# ESP32 register map
Vendor: ESPRESSIF SYSTEMS (SHANGHAI) CO., LTD.; Series: ESP32 Series; File version: 17
CPU: Xtensa LX6 r0p0, little endian, no MPU, FPU, 0 interrupt priority bits
Address unit: 32 bits
Registers are 32-bit, read-write, reset 0x0 unless marked. A register's access mark holds for its fields unless they carry their own. Offsets are from the block's base; [hi:lo] are bit positions; lines under a group give offsets from that group; {n}, {i} and the like mark numbered series.

## MCPWM0 — Motor Control Pulse Width Modulator (MCPWM) Peripheral
Base 0x3FF5E000
Same registers: MCPWM1 0x3FF6C000
0x00 CLK_CFG
  [7:0] CLK_PRESCALE
{0x4+0x10*i} TIMER{i} (i=0..2) group — Cluster TIMER{i}, containing TIMER?_CFG0, TIMER?_CFG1, TIMER?_SYNC, TIMER?_STATUS
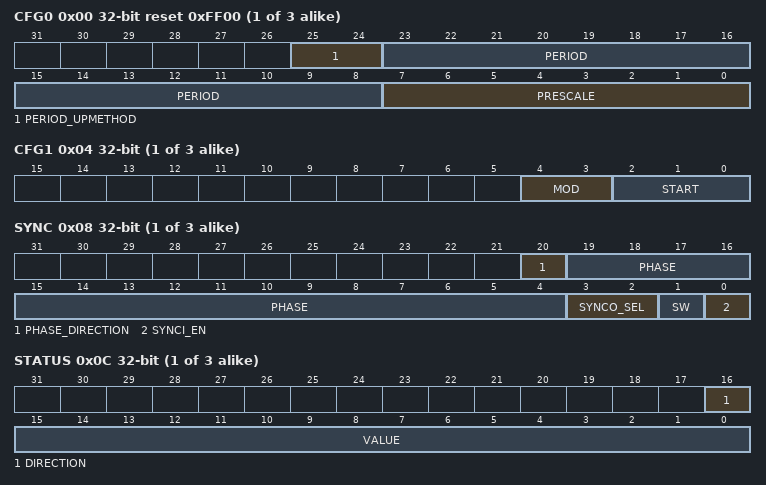
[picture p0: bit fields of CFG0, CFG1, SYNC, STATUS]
  0x00 CFG0 reset 0xFF00 — PWM TIMERx period and update method configuration register.
    [25:24] PERIOD_UPMETHOD, [23:8] PERIOD, [7:0] PRESCALE
  0x04 CFG1 — PWM TIMERx working mode and start/stop control configuration register.
    [4:3] MOD, [2:0] START
  0x08 SYNC — PWM TIMERx sync function configuration register.
    [20] PHASE_DIRECTION, [19:4] PHASE, [3:2] SYNCO_SEL, [1] SW, [0] SYNCI_EN
  0x0C STATUS ro — PWM TIMERx status register.
    [16] DIRECTION, [15:0] VALUE
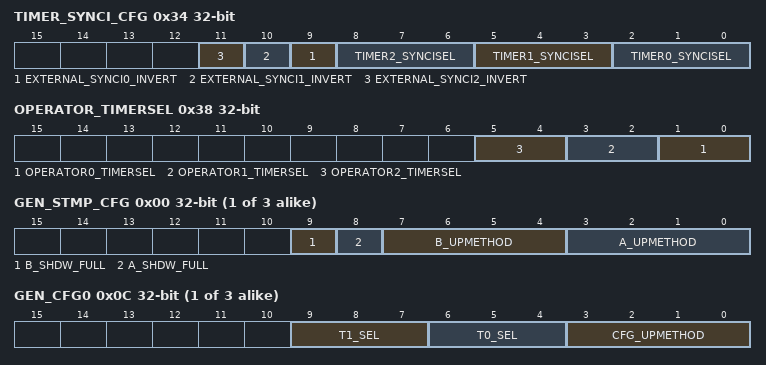
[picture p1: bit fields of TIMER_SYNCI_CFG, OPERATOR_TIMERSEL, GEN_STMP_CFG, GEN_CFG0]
0x34 TIMER_SYNCI_CFG
  [n+9] EXTERNAL_SYNCI{n}_INVERT (n=0..2), [3n+2:3n] TIMER{n}_SYNCISEL (n=0..2)
0x38 OPERATOR_TIMERSEL
  [2n+1:2n] OPERATOR{n}_TIMERSEL (n=0..2)
{0x3C+0x38*i} CH{i} (i=0..2) group — Cluster CH{i}, containing GEN?_STMP_CFG, GEN?_TSTMP_A, GEN?_TSTMP_B, GEN?_CFG0, GEN?_FORCE, GEN?_A, GEN?_B, DT?_CFG, DT?_FED_CFG, DT?_RED_CFG, CARRIER?_CFG, FH?_CFG0, FH?_CFG1, FH?_STATUS
  0x00 GEN_STMP_CFG — Transfer status and update method for time stamp registers A and B
    [9] B_SHDW_FULL, [8] A_SHDW_FULL, [7:4] B_UPMETHOD, [3:0] A_UPMETHOD
  0x04 GEN_TSTMP_A — Shadow register for register A.
    [15:0] A
  0x08 GEN_TSTMP_B — Shadow register for register B.
    [15:0] B
  0x0C GEN_CFG0
    [9:7] T1_SEL, [6:4] T0_SEL, [3:0] CFG_UPMETHOD
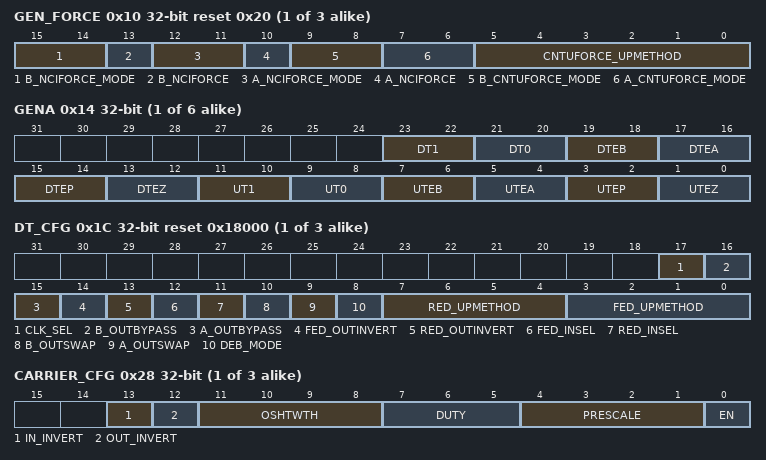
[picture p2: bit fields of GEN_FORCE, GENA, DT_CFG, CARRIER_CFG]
  0x10 GEN_FORCE reset 0x20 — Permissives to force PWMxA and PWMxB outputs by software
    [15:14] B_NCIFORCE_MODE, [13] B_NCIFORCE, [12:11] A_NCIFORCE_MODE, [10] A_NCIFORCE, [9:8] B_CNTUFORCE_MODE, [7:6] A_CNTUFORCE_MODE, [5:0] CNTUFORCE_UPMETHOD
  0x14 GEN{x} (x=A,B; step 0x4) — Actions triggered by events on PWMx{x}
    [23:22] DT1, [21:20] DT0, [19:18] DTEB, [17:16] DTEA, [15:14] DTEP, [13:12] DTEZ, [11:10] UT1, [9:8] UT0, [7:6] UTEB, [5:4] UTEA, [3:2] UTEP, [1:0] UTEZ
  0x1C DT_CFG reset 0x18000 — Dead time type selection and configuration
    [17] CLK_SEL, [16] B_OUTBYPASS, [15] A_OUTBYPASS, [14] FED_OUTINVERT, [13] RED_OUTINVERT, [12] FED_INSEL, [11] RED_INSEL, [10] B_OUTSWAP, [9] A_OUTSWAP, [8] DEB_MODE, [7:4] RED_UPMETHOD, [3:0] FED_UPMETHOD
  0x20 DT_FED_CFG — Shadow register for falling edge delay (FED).
    [15:0] FED
  0x24 DT_RED_CFG — Shadow register for rising edge delay (RED).
    [15:0] RED
  0x28 CARRIER_CFG — Carrier enable and configuratoin
    [13] IN_INVERT, [12] OUT_INVERT, [11:8] OSHTWTH, [7:5] DUTY, [4:1] PRESCALE, [0] EN
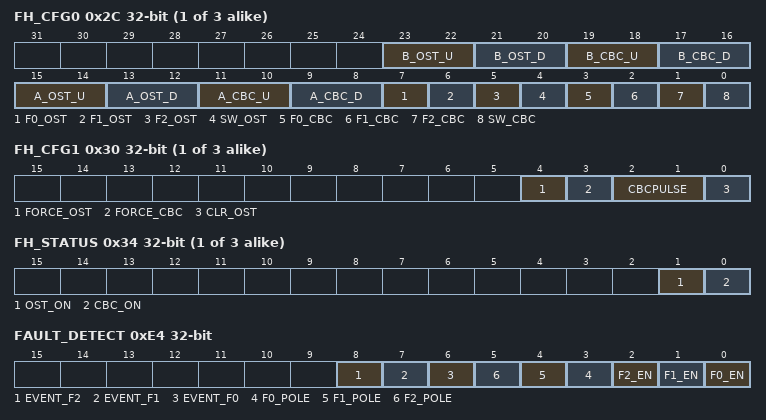
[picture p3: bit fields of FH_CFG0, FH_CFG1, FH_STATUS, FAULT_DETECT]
  0x2C FH_CFG0 — Actions on PWM0A and PWM0B trip events
    [23:22] B_OST_U, [21:20] B_OST_D, [19:18] B_CBC_U, [17:16] B_CBC_D, [15:14] A_OST_U, [13:12] A_OST_D, [11:10] A_CBC_U, [9:8] A_CBC_D, [7] F0_OST, [6] F1_OST, [5] F2_OST, [4] SW_OST, [3] F0_CBC, [2] F1_CBC, [1] F2_CBC, [0] SW_CBC
  0x30 FH_CFG1 — Software triggers for fault handler actions
    [4] FORCE_OST, [3] FORCE_CBC, [2:1] CBCPULSE, [0] CLR_OST
  0x34 FH_STATUS ro — Status of fault events.
    [1] OST_ON, [0] CBC_ON
0xE4 FAULT_DETECT access per field
  [8] EVENT_F2 ro
  [7] EVENT_F1 ro
  [6] EVENT_F0 ro
  [n+3] F{n}_POLE (n=0..2) rw — Configures the polarity of the fault trigger on FAULT{n} source from GPIO matrix.\0: Level low\1: Level high
  [n] F{n}_EN (n=0..2) rw
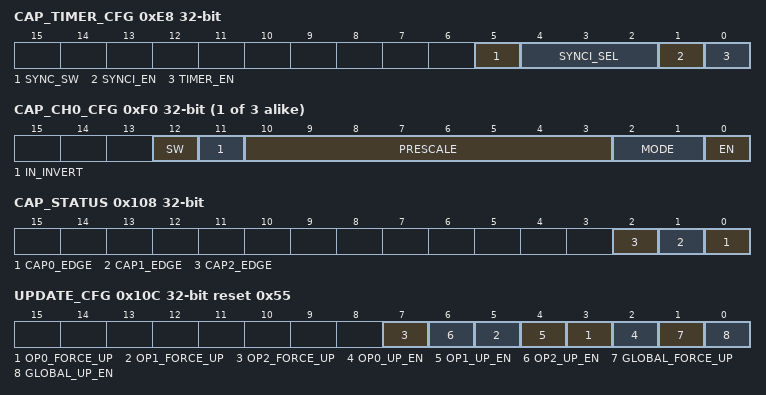
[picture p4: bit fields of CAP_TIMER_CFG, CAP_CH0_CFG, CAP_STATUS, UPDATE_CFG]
0xE8 CAP_TIMER_CFG access per field
  [5] SYNC_SW wo, [4:2] SYNCI_SEL rw, [1] SYNCI_EN rw, [0] TIMER_EN rw
0xEC CAP_TIMER_PHASE
  [31:0] TIMER_PHASE
{0xF0+4i} CAP_CH{i}_CFG (i=0..2) access per field — Capture channel {i} configuration and enable
  [12] SW wo
  [11] IN_INVERT rw
  [10:3] PRESCALE rw
  [2:1] MODE rw — Describes which edges to trigger a capture event
    0=None (Capture nothing); 1=FallingEdge (Capture falling edges); 2=RisingEdge (Capture rising edges); 3=AnyEdge (Capture any edges)
  [0] EN rw
{0xFC+4i} CAP_CH{i} (i=0..2) ro — Value of last capture on channel {i}
  [31:0] VALUE
0x108 CAP_STATUS ro
  [n] CAP{n}_EDGE (n=0..2) — Describes the last captured edge on channel{n}.
    0=Rising edge; 1=Falling edge
0x10C UPDATE_CFG reset 0x55
  [2n+3] OP{n}_FORCE_UP (n=0..2) — A toggle (software invert its value) will trigger a forced update of active registers in PWM operator {n}
  [2n+2] OP{n}_UP_EN (n=0..2)
  [1] GLOBAL_FORCE_UP
  [0] GLOBAL_UP_EN
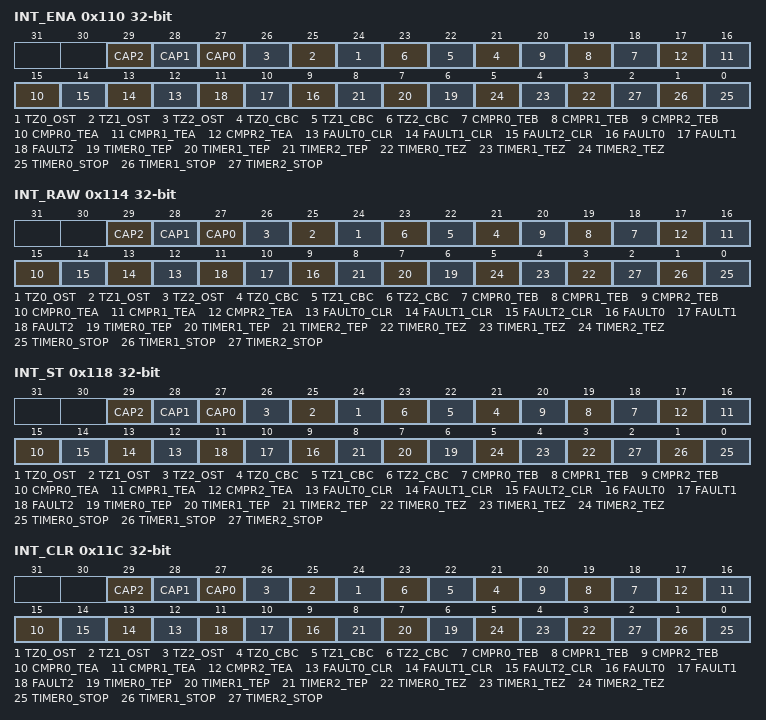
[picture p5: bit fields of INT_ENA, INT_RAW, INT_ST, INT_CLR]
0x110 INT_ENA
  [n+27] CAP{n} (n=0..2) — The interrupt enable bit for the capture{n} event.
  [n+24] TZ{n}_OST (n=0..2) — The interrupt enable bit for the fault handler{n} one-shot mode action.
  [n+21] TZ{n}_CBC (n=0..2) — The interrupt enable bit for the fault handler{n} cycle-by-cycle mode action.
  [n+18] CMPR{n}_TEB (n=0..2) — The interrupt enable bit for the operator{n} compare B event.
  [n+15] CMPR{n}_TEA (n=0..2) — The interrupt enable bit for the operator{n} compare A event.
  [n+12] FAULT{n}_CLR (n=0..2) — The interrupt enable bit for the fault{n} clear event.
  [n+9] FAULT{n} (n=0..2) — The interrupt enable bit for the fault{n} event.
  [n+6] TIMER{n}_TEP (n=0..2) — The interrupt enable bit for the timer{n} period event.
  [n+3] TIMER{n}_TEZ (n=0..2) — The interrupt enable bit for the timer{n} zero event.
  [n] TIMER{n}_STOP (n=0..2) — The interrupt enable bit for the timer{n} stop event.
0x114 INT_RAW
  [n+27] CAP{n} (n=0..2) — The interrupt raw bit for the capture{n} event.
  [n+24] TZ{n}_OST (n=0..2) — The interrupt raw bit for the fault handler{n} one-shot mode action.
  [n+21] TZ{n}_CBC (n=0..2) — The interrupt raw bit for the fault handler{n} cycle-by-cycle mode action.
  [n+18] CMPR{n}_TEB (n=0..2) — The interrupt raw bit for the operator{n} compare B event.
  [n+15] CMPR{n}_TEA (n=0..2) — The interrupt raw bit for the operator{n} compare A event.
  [n+12] FAULT{n}_CLR (n=0..2) — The interrupt raw bit for the fault{n} clear event.
  [n+9] FAULT{n} (n=0..2) — The interrupt raw bit for the fault{n} event.
  [n+6] TIMER{n}_TEP (n=0..2) — The interrupt raw bit for the timer{n} period event.
  [n+3] TIMER{n}_TEZ (n=0..2) — The interrupt raw bit for the timer{n} zero event.
  [n] TIMER{n}_STOP (n=0..2) — The interrupt raw bit for the timer{n} stop event.
0x118 INT_ST ro
  [n+27] CAP{n} (n=0..2) — The interrupt status bit for the capture{n} event.
  [n+24] TZ{n}_OST (n=0..2) — The interrupt status bit for the fault handler{n} one-shot mode action.
  [n+21] TZ{n}_CBC (n=0..2) — The interrupt status bit for the fault handler{n} cycle-by-cycle mode action.
  [n+18] CMPR{n}_TEB (n=0..2) — The interrupt status bit for the operator{n} compare B event.
  [n+15] CMPR{n}_TEA (n=0..2) — The interrupt status bit for the operator{n} compare A event.
  [n+12] FAULT{n}_CLR (n=0..2) — The interrupt status bit for the fault{n} clear event.
  [n+9] FAULT{n} (n=0..2) — The interrupt status bit for the fault{n} event.
  [n+6] TIMER{n}_TEP (n=0..2) — The interrupt status bit for the timer{n} period event.
  [n+3] TIMER{n}_TEZ (n=0..2) — The interrupt status bit for the timer{n} zero event.
  [n] TIMER{n}_STOP (n=0..2) — The interrupt status bit for the timer{n} stop event.
0x11C INT_CLR wo
  [n+27] CAP{n} (n=0..2) write-1-clears — The interrupt clear bit for the capture{n} event.
  [n+24] TZ{n}_OST (n=0..2) write-1-clears — The interrupt clear bit for the fault handler{n} one-shot mode action.
  [n+21] TZ{n}_CBC (n=0..2) write-1-clears — The interrupt clear bit for the fault handler{n} cycle-by-cycle mode action.
  [n+18] CMPR{n}_TEB (n=0..2) write-1-clears — The interrupt clear bit for the operator{n} compare B event.
  [n+15] CMPR{n}_TEA (n=0..2) write-1-clears — The interrupt clear bit for the operator{n} compare A event.
  [n+12] FAULT{n}_CLR (n=0..2) write-1-clears — The interrupt clear bit for the fault{n} clear event.
  [n+9] FAULT{n} (n=0..2) write-1-clears — The interrupt clear bit for the fault{n} event.
  [n+6] TIMER{n}_TEP (n=0..2) write-1-clears — The interrupt clear bit for the timer{n} period event.
  [n+3] TIMER{n}_TEZ (n=0..2) write-1-clears — The interrupt clear bit for the timer{n} zero event.
  [n] TIMER{n}_STOP (n=0..2) write-1-clears — The interrupt clear bit for the timer{n} stop event.
0x120 CLK
  [0] EN
0x124 VERSION
